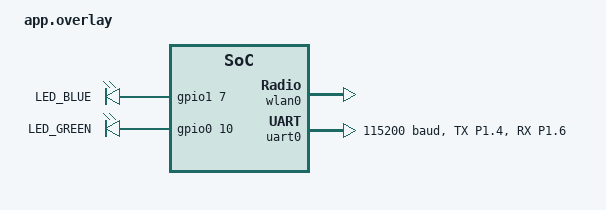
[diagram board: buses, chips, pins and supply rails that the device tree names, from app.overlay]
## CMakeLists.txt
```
#
# Copyright (c) 2022 Nordic Semiconductor ASA
#
# SPDX-License-Identifier: LicenseRef-Nordic-5-Clause
#

cmake_minimum_required(VERSION 3.20.0)

find_package(Zephyr REQUIRED HINTS $ENV{ZEPHYR_BASE})
project(nrf_wifi_sta)

target_include_directories(app PUBLIC
	${CMAKE_CURRENT_SOURCE_DIR}/src
	${ZEPHYR_BASE}/subsys/net/ip
)

target_sources(app PRIVATE
	src/main.c
	src/wt_app.c
	src/wt_ble.c
	src/wt_common.c
	src/wt_leds.c
	src/wt_radio.c
	src/wt_shell.c
	src/wt_stream.c
	src/wt_wifi.c
)
```

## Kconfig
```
#
# Copyright (c) 2022 Nordic Semiconductor
#
# SPDX-License-Identifier: LicenseRef-Nordic-5-Clause
#

source "Kconfig.zephyr"

menu "Nordic Sta sample"

config CONNECTION_IDLE_TIMEOUT
	int "Time to be waited for a station to connect"
	default 30

config NRF70_QSPI_ENCRYPTION_KEY
	string "16 bytes QSPI encryption key, only for testing purposes"
	depends on BOARD_NRF7002DK_NRF5340_CPUAPP
	help
	  Specify the QSPI encryption key

config STA_CONN_TIMEOUT_SEC
	int "Overall Connection timeout i.e., time to be waited for a station to connect and get an IP address"
	# Zephyr DHCP retry is 1 minute, so set the default to 70 seconds
	default 70
	# 512 has no special meaning, just a reasonable upper limit
	range 0 512
	help
	  Specify the connection timeout, in seconds. This is the overall timeout i.e., time to be waited for
	  a station to connect and get an IP address. DHCP retries should be taken into account when setting
	  this value. If the timeout is set to 0, the connection will not timeout.

choice WT02E40E_DEFAULT_RADIO_MODE
	prompt "Default WT02E40E radio mode"
	default WT02E40E_DEFAULT_BLE
	help
	  Select which radio path starts automatically at boot. Wi-Fi can be
	  left disabled while the external antenna is missing, then started
	  from the UART/RTT shell later.

config WT02E40E_DEFAULT_IDLE
	bool "Idle, commands only"

config WT02E40E_DEFAULT_BLE
	bool "BLE advertising"

config WT02E40E_DEFAULT_WIFI
	bool "Wi-Fi station"

config WT02E40E_DEFAULT_BOTH
	bool "BLE advertising and Wi-Fi station"

endchoice

config STA_SAMPLE_START_WIFI_THREAD_STACK_SIZE
	int "Stack size for Wi-Fi start thread"
	default 4096
	help
	  Set the stack size for the Wi-Fi start thread.

endmenu
```

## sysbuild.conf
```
# Build nRF7002 Wi-Fi support and the nRF5340 network-core BLE controller image.
SB_CONFIG_WIFI_NRF70=y
SB_CONFIG_NETCORE_HCI_IPC=y
```

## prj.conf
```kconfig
# WT02E40E nRF5340 + nRF7002 Wi-Fi/BLE command bring-up.

# Default boot behavior while the Wi-Fi antenna is missing.
CONFIG_WT02E40E_DEFAULT_BLE=y

# Wi-Fi
CONFIG_WIFI=y
CONFIG_WIFI_NRF70=y
CONFIG_WIFI_NM_WPA_SUPPLICANT=y
CONFIG_WIFI_READY_LIB=y

# Wi-Fi credentials. Static credentials are the compiled fallback, and the UART/RTT
# shell can store a runtime override in the Zephyr credentials backend.
CONFIG_WIFI_CREDENTIALS=y
CONFIG_WIFI_CREDENTIALS_MAX_ENTRIES=4
CONFIG_WIFI_CREDENTIALS_BACKEND_SETTINGS=y
CONFIG_SETTINGS=y
CONFIG_SETTINGS_NVS=y
CONFIG_NVS=y
CONFIG_FLASH=y
CONFIG_FLASH_PAGE_LAYOUT=y
CONFIG_FLASH_MAP=y
CONFIG_WIFI_CREDENTIALS_STATIC=y
CONFIG_WIFI_CREDENTIALS_STATIC_SSID="Myssid"
CONFIG_WIFI_CREDENTIALS_STATIC_PASSWORD="Mypassword"

# BLE peripheral advertising.
CONFIG_BT=y
CONFIG_BT_PERIPHERAL=y
CONFIG_BT_DEVICE_NAME="WT02E40E-CMD"
CONFIG_BT_DEVICE_NAME_DYNAMIC=y
CONFIG_BT_DEVICE_NAME_MAX=32
CONFIG_BT_MAX_CONN=1
CONFIG_BT_BUF_ACL_TX_COUNT=3
CONFIG_BT_BUF_EVT_RX_COUNT=10
CONFIG_BT_RX_STACK_SIZE=2048

# BLE ATT MTU / L2CAP buffers.
# App-level command/status payloads are capped at 255 bytes, but notifications use
# the negotiated ATT MTU dynamically. With MTU 256, usable ATT payload is 253 bytes.
CONFIG_BT_L2CAP_TX_MTU=256
CONFIG_BT_BUF_ACL_RX_SIZE=260
CONFIG_BT_BUF_ACL_TX_SIZE=260

# UART/RTT command shell.
CONFIG_SERIAL=y
CONFIG_CONSOLE=y
CONFIG_UART_CONSOLE=y
CONFIG_UART_INTERRUPT_DRIVEN=y
CONFIG_SHELL=y
CONFIG_SHELL_BACKEND_SERIAL=y
CONFIG_SHELL_BACKEND_RTT=y
CONFIG_SHELL_STACK_SIZE=4096
CONFIG_SHELL_CMDS_RESIZE=n
CONFIG_USE_SEGGER_RTT=y

# Networking
CONFIG_NETWORKING=y
CONFIG_NET_SOCKETS=y
CONFIG_NET_LOG=y
CONFIG_NET_IPV4=y
CONFIG_NET_UDP=y
CONFIG_NET_TCP=y
CONFIG_NET_DHCPV4=y

CONFIG_NET_PKT_RX_COUNT=16
CONFIG_NET_PKT_TX_COUNT=16
CONFIG_NRF70_RX_NUM_BUFS=16

# Wi-Fi memory tuning from Nordic STA sample.
CONFIG_NET_BUF_RX_COUNT=16
CONFIG_NET_BUF_TX_COUNT=32
CONFIG_HEAP_MEM_POOL_SIZE=37000
CONFIG_HEAP_MEM_POOL_IGNORE_MIN=y
CONFIG_NRF_WIFI_CTRL_HEAP_SIZE=20000
CONFIG_NRF_WIFI_DATA_HEAP_SIZE=40000
CONFIG_NET_TC_TX_COUNT=1

CONFIG_NET_IF_UNICAST_IPV4_ADDR_COUNT=1
CONFIG_NET_MAX_CONTEXTS=5
CONFIG_NET_CONTEXT_SYNC_RECV=y

CONFIG_NET_L2_ETHERNET=y
CONFIG_NET_L2_ETHERNET_MGMT=y

CONFIG_NET_CONFIG_SETTINGS=y
CONFIG_NET_CONFIG_INIT_TIMEOUT=0
CONFIG_NET_CONFIG_MY_IPV4_ADDR="192.168.1.99"
CONFIG_NET_CONFIG_MY_IPV4_NETMASK="255.255.255.0"
CONFIG_NET_CONFIG_MY_IPV4_GW="192.168.1.1"

CONFIG_ZVFS_POLL_MAX=10

# Memory
CONFIG_MAIN_STACK_SIZE=5200
CONFIG_NET_TX_STACK_SIZE=4096
CONFIG_NET_RX_STACK_SIZE=4096
CONFIG_STA_SAMPLE_START_WIFI_THREAD_STACK_SIZE=6144
CONFIG_SYSTEM_WORKQUEUE_STACK_SIZE=4096

# Kernel
CONFIG_GPIO=y
CONFIG_ENTROPY_GENERATOR=y
CONFIG_INIT_STACKS=y

# Logging / debug
CONFIG_LOG=y
CONFIG_LOG_DEFAULT_LEVEL=3
CONFIG_LOG_BUFFER_SIZE=4096
CONFIG_LOG_BACKEND_RTT=n
CONFIG_LOG_BACKEND_UART=n
CONFIG_SHELL_LOG_BACKEND=y
CONFIG_POSIX_TIMERS=y
CONFIG_STACK_SENTINEL=y
CONFIG_DEBUG_COREDUMP=y
CONFIG_DEBUG_COREDUMP_BACKEND_LOGGING=y
CONFIG_DEBUG_COREDUMP_MEMORY_DUMP_MIN=y

# Printing scan/status results can put pressure on queues in crowded environments.
CONFIG_NET_MGMT_EVENT_QUEUE_TIMEOUT=5000

# Reboot command support
CONFIG_REBOOT=y
```

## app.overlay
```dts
#include <zephyr/dt-bindings/pinctrl/nrf-pinctrl.h>

/*
 * WT02E40E local MAC address for the nRF7002 Wi-Fi interface when OTP
 * is not programmed. This is locally administered, not a public OUI.
 */
&wlan0 {
	local-mac-address = [f6 ce 36 00 00 01];
};

/*
 * WT02E40E carrier schematic:
 *   Blue LED:  P1.07 -> LED/resistor -> GND
 *   Green LED: P0.10 -> LED/resistor -> GND
 */
&led0 {
	gpios = <&gpio1 7 GPIO_ACTIVE_HIGH>;
	label = "LED_BLUE";
};

&led1 {
	gpios = <&gpio0 10 GPIO_ACTIVE_HIGH>;
	label = "LED_GREEN";
};

/*
 * UART command shell on the carrier nets:
 *   nRF P1.04 UART_TX -> PA23/RX1 net
 *   nRF P1.06 UART_RX -> PA22/TX1 net
 */
&pinctrl {
	uart0_wt02e40e_default: uart0_wt02e40e_default {
		group1 {
			psels = <NRF_PSEL(UART_TX, 1, 4)>,
				<NRF_PSEL(UART_RX, 1, 6)>;
		};
	};

	uart0_wt02e40e_sleep: uart0_wt02e40e_sleep {
		group1 {
			psels = <NRF_PSEL(UART_TX, 1, 4)>,
				<NRF_PSEL(UART_RX, 1, 6)>;
			low-power-enable;
		};
	};
};

&uart0 {
	status = "okay";
	current-speed = <115200>;
	pinctrl-0 = <&uart0_wt02e40e_default>;
	pinctrl-1 = <&uart0_wt02e40e_sleep>;
	pinctrl-names = "default", "sleep";
};
```

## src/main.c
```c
/*
 * Copyright (c) 2022 Nordic Semiconductor ASA
 *
 * SPDX-License-Identifier: LicenseRef-Nordic-5-Clause
 */

/** @file
 * @brief WT02E40E Wi-Fi/BLE command bridge entry point.
 */

#include <errno.h>

#include <zephyr/kernel.h>
#include <zephyr/logging/log.h>
#include <zephyr/sys/util.h>

#include "wt_app.h"
#include "wt_ble.h"
#include "wt_leds.h"
#include "wt_radio.h"
#include "wt_wifi.h"

LOG_MODULE_REGISTER(wt_main, CONFIG_LOG_DEFAULT_LEVEL);

int main(void)
{
	int ret;

	LOG_INF("Starting %s with CPU frequency: %d MHz", CONFIG_BOARD, SystemCoreClock / MHZ(1));

	wt_leds_start();
	wt_ble_init();

	ret = wt_wifi_init();
	if (ret) {
		return ret;
	}

#ifdef CONFIG_WIFI_READY_LIB
	ret = wt_wifi_register_ready_callback();
	if (ret) {
		return ret;
	}
	wt_wifi_start_worker();
#else
	LOG_ERR("CONFIG_WIFI_READY_LIB is required for this command sample");
	return -ENOTSUP;
#endif

	ret = wt_app_settings_init();
	if (ret) {
		LOG_WRN("App settings load skipped/failed: %d", ret);
	}

	k_sleep(K_SECONDS(1));
	wt_radio_apply_default_mode();

	while (1) {
		k_sleep(K_FOREVER);
	}

	return 0;
}
```

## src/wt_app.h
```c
#ifndef WT_APP_H
#define WT_APP_H

#include <stdbool.h>
#include <stddef.h>
#include <stdint.h>

#define WT_APP_FW_VERSION "0.3.9-wifi-led-idle"

int wt_app_settings_init(void);
int wt_app_config_save(void);
int wt_app_config_reset(void);

const char *wt_app_boot_mode_get(void);
int wt_app_boot_mode_set(const char *mode);

int wt_app_version_format(char *buf, size_t size);
int wt_app_id_format(char *buf, size_t size);
int wt_app_config_format(char *buf, size_t size, bool json);
int wt_app_ble_status_format(char *buf, size_t size, bool json);
int wt_app_wifi_status_format(char *buf, size_t size, bool json);
int wt_app_fw_status_format(char *buf, size_t size);

int wt_app_parse_delay_ms(const char *text, uint32_t *delay_ms);
int wt_app_delayed_radio_apply(const char *mode_or_action, uint32_t delay_ms);
int wt_app_reboot_schedule(bool bootloader, uint32_t delay_ms);

bool wt_app_bridge_ble_enabled(void);
bool wt_app_bridge_uart_enabled(void);
bool wt_app_bridge_wifi_enabled(void);
const char *wt_app_bridge_target_ip_get(void);
uint16_t wt_app_bridge_target_port_get(void);
int wt_app_bridge_set(const char *path, bool enable);
int wt_app_bridge_target_set(const char *ip, const char *port_text);
int wt_app_bridge_status_format(char *buf, size_t size, bool json);
int wt_app_bridge_send(const uint8_t *data, size_t len, char *rsp, size_t rsp_len);

int wt_app_ping_execute(char **argv, size_t argc, char *rsp, size_t rsp_len);
int wt_app_boot_command(char **argv, size_t argc, char *rsp, size_t rsp_len);
int wt_app_bridge_command(char **argv, size_t argc, char *rsp, size_t rsp_len);
int wt_app_fw_command(char **argv, size_t argc, char *rsp, size_t rsp_len);
int wt_app_led_command(char **argv, size_t argc, char *rsp, size_t rsp_len);

#endif /* WT_APP_H */
```

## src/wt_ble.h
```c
#ifndef WT_BLE_H
#define WT_BLE_H

#include <stdbool.h>
#include <stddef.h>
#include <stdint.h>

bool wt_ble_is_requested(void);
bool wt_ble_is_ready(void);
bool wt_ble_is_advertising(void);
bool wt_ble_is_connected(void);
bool wt_ble_tx_notify_is_enabled(void);
bool wt_ble_status_notify_is_enabled(void);
bool wt_ble_cmd_response_notify_is_enabled(void);
const char *wt_ble_name_get(void);
int wt_ble_name_set(const char *name);

void wt_ble_init(void);
int wt_ble_service_start(void);
int wt_ble_service_stop(void);
int wt_ble_transmit_payload(const uint8_t *data, size_t len);
int wt_ble_status_format(char *buf, size_t size);

#endif /* WT_BLE_H */
```

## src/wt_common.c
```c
#include <errno.h>
#include <stdint.h>
#include <stdlib.h>
#include <string.h>

#include <zephyr/sys/util.h>

#include "wt_common.h"

const char *wt_onoff_txt(bool state)
{
	return state ? "on" : "off";
}

int wt_build_payload_from_argv(size_t start_arg, size_t argc, char **argv,
				       char *buf, size_t buf_len)
{
	size_t offset = 0;

	if (start_arg >= argc) {
		return -EINVAL;
	}

	for (size_t i = start_arg; i < argc; i++) {
		const char *arg = argv[i];
		size_t arg_len = strlen(arg);

		if (i > start_arg) {
			if (offset + 1 >= buf_len) {
				return -EMSGSIZE;
			}
			buf[offset++] = ' ';
		}

		if (offset + arg_len >= buf_len) {
			return -EMSGSIZE;
		}

		memcpy(&buf[offset], arg, arg_len);
		offset += arg_len;
	}

	buf[offset] = '\0';
	return (int)offset;
}

static bool wt_is_cmd_space(char c)
{
	return c == ' ' || c == '\t' || c == '\r' || c == '\n';
}

static char wt_unescape_char(char c)
{
	switch (c) {
	case 'n':
		return '\n';
	case 'r':
		return '\r';
	case 't':
		return '\t';
	default:
		return c;
	}
}

int wt_split_args_quoted(char *line, char **argv, size_t argv_max)
{
	char *read = line;
	size_t argc = 0;

	if (!line || !argv || argv_max == 0) {
		return -EINVAL;
	}

	while (*read) {
		char *write;
		char quote = '\0';

		while (*read && wt_is_cmd_space(*read)) {
			*read++ = '\0';
		}

		if (!*read) {
			break;
		}

		if (argc >= argv_max) {
			return -E2BIG;
		}

		argv[argc++] = read;
		write = read;

		while (*read) {
			char c = *read++;

			if (quote) {
				if (c == '\\' && *read) {
					*write++ = wt_unescape_char(*read++);
					continue;
				}
				if (c == quote) {
					quote = '\0';
					continue;
				}
				*write++ = c;
				continue;
			}

			if (c == '\'' || c == '"') {
				quote = c;
				continue;
			}

			if (wt_is_cmd_space(c)) {
				break;
			}

			if (c == '\\' && *read) {
				*write++ = wt_unescape_char(*read++);
				continue;
			}

			*write++ = c;
		}

		if (quote) {
			return -EINVAL;
		}

		*write = '\0';
	}

	return (int)argc;
}

int wt_parse_udp_port(const char *port_text, uint16_t *port)
{
	char *end = NULL;
	long parsed = strtol(port_text, &end, 10);

	if (!end || *end != '\0' || parsed <= 0 || parsed > UINT16_MAX) {
		return -EINVAL;
	}

	*port = (uint16_t)parsed;
	return 0;
}
```

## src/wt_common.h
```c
#ifndef WT_COMMON_H
#define WT_COMMON_H

#include <stddef.h>
#include <stdint.h>
#include <stdbool.h>

const char *wt_onoff_txt(bool state);
int wt_build_payload_from_argv(size_t start_arg, size_t argc, char **argv,
				       char *buf, size_t buf_len);
int wt_parse_udp_port(const char *port_text, uint16_t *port);
int wt_split_args_quoted(char *line, char **argv, size_t argv_max);

#endif /* WT_COMMON_H */
```

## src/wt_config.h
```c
#ifndef WT_CONFIG_H
#define WT_CONFIG_H

#define STATUS_POLLING_MS 300
#define LED_SLEEP_TIME_MS 250
#define WT_BLE_NOTIFY_RETRY_COUNT 8
#define WT_BLE_NOTIFY_RETRY_DELAY_MS 20
#define WT_BLE_NOTIFY_INTER_CHUNK_DELAY_MS 12
#define WT_TX_PAYLOAD_MAX 244
#define WT_BLE_NOTIFY_APP_PAYLOAD_MAX 244
#define WT_BLE_STREAM_CHUNK_OVERHEAD 8
#define WT_BLE_STATUS_TEXT_MAX 250
#define WT_BLE_CMD_TEXT_MAX 255
#define WT_BLE_CMD_RSP_TEXT_MAX 250
#define WT_BLE_STATUS_PING_MS 5000
#define WT_BLE_ADV_RESTART_DELAY_MS 250
#define WT_BLE_SELF_STOP_DELAY_MS 500
#define WT_WIFI_CRED_TIMEOUT_SEC CONFIG_STA_CONN_TIMEOUT_SEC

#define WT_WIFI_CMD_UDP_PORT 5001
#define WT_WIFI_CMD_RX_TEXT_MAX 255
#define WT_WIFI_CMD_RSP_TEXT_MAX 250
#define WT_WIFI_CMD_THREAD_STACK_SIZE 4096
#define WT_WIFI_CMD_THREAD_PRIORITY 7
#define WT_WIFI_DISCOVERY_UDP_PORT 5000
#define WT_WIFI_DISCOVERY_INTERVAL_MS 5000
#define WT_WIFI_DISCOVERY_PAYLOAD_MAX 250
#define WT_WIFI_SCAN_MAX_RESULTS 10
#define WT_WIFI_SCAN_TIMEOUT_MS 12000
#define WT_BLE_NAME_MAX 31

#define WT_APP_BOOT_MODE_MAX 8
#define WT_APP_DELAYED_ACTION_MAX 16
#define WT_APP_REBOOT_DELAY_MS 500
#define WT_APP_BRIDGE_TARGET_MAX 47

#endif /* WT_CONFIG_H */
```

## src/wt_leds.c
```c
#include <errno.h>
#include <stdbool.h>
#include <stddef.h>
#include <stdint.h>
#include <string.h>

#include <zephyr/drivers/gpio.h>
#include <zephyr/kernel.h>
#include <zephyr/logging/log.h>
#include <zephyr/sys/atomic.h>
#include <zephyr/sys/printk.h>
#include <zephyr/sys/util.h>

#include "wt_ble.h"
#include "wt_config.h"
#include "wt_leds.h"
#include "wt_wifi.h"

LOG_MODULE_REGISTER(wt_leds, CONFIG_LOG_DEFAULT_LEVEL);

#define WT_LED_MASK_BLE BIT(0)
#define WT_LED_MASK_WIFI BIT(1)
#define WT_LED_MASK_ACTIVITY BIT(2)
#define WT_LED_MASK_ALERT BIT(3)
#define WT_LED_ACTIVITY_TICKS 4
#define WT_LED_BLE_REPORT_TICKS 2
#define WT_LED_ALERT_TICKS 12
#define WT_LED_TEST_TICKS 24

#if DT_NODE_HAS_STATUS(DT_ALIAS(led0), okay)
static const struct gpio_dt_spec led_ble = GPIO_DT_SPEC_GET(DT_ALIAS(led0), gpios);
#define WT_HAS_LED_BLE 1
#else
#define WT_HAS_LED_BLE 0
#endif

#if DT_NODE_HAS_STATUS(DT_ALIAS(led1), okay)
static const struct gpio_dt_spec led_wifi = GPIO_DT_SPEC_GET(DT_ALIAS(led1), gpios);
#define WT_HAS_LED_WIFI 1
#else
#define WT_HAS_LED_WIFI 0
#endif

#if DT_NODE_HAS_STATUS(DT_ALIAS(led2), okay)
static const struct gpio_dt_spec led_activity = GPIO_DT_SPEC_GET(DT_ALIAS(led2), gpios);
#define WT_HAS_LED_ACTIVITY 1
#else
#define WT_HAS_LED_ACTIVITY 0
#endif

#if DT_NODE_HAS_STATUS(DT_ALIAS(led3), okay)
static const struct gpio_dt_spec led_alert = GPIO_DT_SPEC_GET(DT_ALIAS(led3), gpios);
#define WT_HAS_LED_ALERT 1
#else
#define WT_HAS_LED_ALERT 0
#endif

static atomic_t ble_activity_ticks;
static atomic_t ble_report_ticks;
static atomic_t wifi_activity_ticks;
static atomic_t bridge_activity_ticks;
static atomic_t alert_activity_ticks;
static atomic_t test_ticks;
static atomic_t test_mask;

static int configure_indicator_led(const struct gpio_dt_spec *led, const char *name)
{
	int ret;

	if (!led) {
		return -ENODEV;
	}

	if (!gpio_is_ready_dt(led)) {
		LOG_ERR("%s GPIO device is not ready", name);
		return -ENODEV;
	}

	ret = gpio_pin_configure_dt(led, GPIO_OUTPUT_INACTIVE);
	if (ret < 0) {
		LOG_ERR("Failed to configure %s LED: %d", name, ret);
		return ret;
	}

	return 0;
}

static void set_indicator_led(const struct gpio_dt_spec *led, int on)
{
	if (led && gpio_is_ready_dt(led)) {
		gpio_pin_set_dt(led, on);
	}
}

static bool consume_pulse(atomic_t *ticks)
{
	atomic_val_t value = atomic_get(ticks);

	if (value <= 0) {
		return false;
	}

	atomic_dec(ticks);
	return true;
}

static bool led_test_applies(uint32_t mask, uint32_t bit)
{
	return (mask & bit) != 0U;
}

static bool led_target_mask(const char *target, uint32_t *mask)
{
	if (!target || !mask) {
		return false;
	}

	if (!strcmp(target, "all") || !strcmp(target, "test")) {
		*mask = WT_LED_MASK_BLE | WT_LED_MASK_WIFI | WT_LED_MASK_ACTIVITY | WT_LED_MASK_ALERT;
		return true;
	}
	if (!strcmp(target, "ble") || !strcmp(target, "bt")) {
		*mask = WT_LED_MASK_BLE;
		return true;
	}
	if (!strcmp(target, "wifi") || !strcmp(target, "wi-fi")) {
		*mask = WT_LED_MASK_WIFI;
		return true;
	}
	if (!strcmp(target, "bridge") || !strcmp(target, "activity") || !strcmp(target, "tx")) {
		*mask = WT_LED_MASK_ACTIVITY;
		return true;
	}
	if (!strcmp(target, "alert") || !strcmp(target, "error") || !strcmp(target, "err")) {
		*mask = WT_LED_MASK_ALERT;
		return true;
	}

	return false;
}

static void indicator_leds_thread(void *p1, void *p2, void *p3)
{
	ARG_UNUSED(p1);
	ARG_UNUSED(p2);
	ARG_UNUSED(p3);

	uint32_t tick = 0;

#if WT_HAS_LED_BLE
	(void)configure_indicator_led(&led_ble, "ble/status");
#endif
#if WT_HAS_LED_WIFI
	(void)configure_indicator_led(&led_wifi, "wifi/status");
#endif
#if WT_HAS_LED_ACTIVITY
	(void)configure_indicator_led(&led_activity, "bridge/activity");
#endif
#if WT_HAS_LED_ALERT
	(void)configure_indicator_led(&led_alert, "alert/error");
#endif

	while (1) {
		const bool fast = (tick & 1U) != 0U;
		const bool medium = ((tick / 2U) & 1U) != 0U;
		const bool slow = ((tick / 4U) & 1U) != 0U;
		const bool heartbeat = (tick % 8U) == 0U;
		const bool double_pulse = (tick % 12U) == 0U || (tick % 12U) == 2U;
		bool ble_led_on = false;
		bool wifi_led_on = false;
		bool activity_led_on = false;
		bool alert_led_on = false;
		atomic_val_t active_test_ticks = atomic_get(&test_ticks);
		uint32_t active_test_mask = (uint32_t)atomic_get(&test_mask);

		if (wt_ble_is_connected()) {
			ble_led_on = true;
		} else if (wt_ble_is_advertising()) {
			ble_led_on = medium;
		} else if (wt_ble_is_requested() && wt_ble_is_ready()) {
			ble_led_on = heartbeat;
		} else if (wt_ble_is_requested()) {
			ble_led_on = slow;
		}

		if (wt_wifi_scan_is_running()) {
			wifi_led_on = fast;
		} else if (wt_wifi_has_ipv4()) {
			wifi_led_on = true;
		} else if (wt_wifi_is_associated()) {
			wifi_led_on = double_pulse;
		} else if (wt_wifi_is_requested()) {
			wifi_led_on = slow;
		}

		if (consume_pulse(&ble_activity_ticks)) {
			ble_led_on = true;
			activity_led_on = true;
		}
		if (consume_pulse(&ble_report_ticks)) {
			ble_led_on = wt_ble_is_connected() ? false : true;
			activity_led_on = true;
		}
		if (consume_pulse(&wifi_activity_ticks)) {
			wifi_led_on = true;
			activity_led_on = true;
		}
		if (consume_pulse(&bridge_activity_ticks)) {
			activity_led_on = true;
		}
		if (consume_pulse(&alert_activity_ticks)) {
			alert_led_on = fast;
		}

		if (active_test_ticks > 0) {
			atomic_dec(&test_ticks);
			if (led_test_applies(active_test_mask, WT_LED_MASK_BLE)) {
				ble_led_on = fast;
			}
			if (led_test_applies(active_test_mask, WT_LED_MASK_WIFI)) {
				wifi_led_on = fast;
			}
			if (led_test_applies(active_test_mask, WT_LED_MASK_ACTIVITY)) {
				activity_led_on = fast;
			}
			if (led_test_applies(active_test_mask, WT_LED_MASK_ALERT)) {
				alert_led_on = fast;
			}
		}

#if WT_HAS_LED_BLE
		set_indicator_led(&led_ble, ble_led_on ? 1 : 0);
#endif
#if WT_HAS_LED_WIFI
		set_indicator_led(&led_wifi, wifi_led_on ? 1 : 0);
#endif
#if WT_HAS_LED_ACTIVITY
		set_indicator_led(&led_activity, activity_led_on ? 1 : 0);
#endif
#if WT_HAS_LED_ALERT
		set_indicator_led(&led_alert, alert_led_on ? 1 : 0);
#endif

		tick++;
		k_msleep(LED_SLEEP_TIME_MS);
	}
}

K_THREAD_DEFINE(led_thread_id, 1024, indicator_leds_thread, NULL, NULL, NULL, 7, 0, 0);

void wt_leds_start(void)
{
	/* LED thread starts automatically through K_THREAD_DEFINE. */
}

void wt_leds_ble_activity(void)
{
	atomic_set(&ble_activity_ticks, WT_LED_ACTIVITY_TICKS);
}

void wt_leds_ble_report_activity(void)
{
	atomic_set(&ble_report_ticks, WT_LED_BLE_REPORT_TICKS);
}

void wt_leds_wifi_activity(void)
{
	atomic_set(&wifi_activity_ticks, WT_LED_ACTIVITY_TICKS);
}

void wt_leds_bridge_activity(void)
{
	atomic_set(&bridge_activity_ticks, WT_LED_ACTIVITY_TICKS);
}

void wt_leds_error_activity(void)
{
	atomic_set(&alert_activity_ticks, WT_LED_ALERT_TICKS);
}

int wt_leds_test(const char *target)
{
	uint32_t mask;

	if (!target || target[0] == '\0') {
		target = "all";
	}

	if (!led_target_mask(target, &mask)) {
		return -EINVAL;
	}

	atomic_set(&test_mask, (atomic_val_t)mask);
	atomic_set(&test_ticks, WT_LED_TEST_TICKS);
	return 0;
}

int wt_leds_status_format(char *buf, size_t size)
{
	if (!buf || size == 0) {
		return -EINVAL;
	}

	return snprintk(buf, size,
		"led status ble=conn solid/cmd-rsp+tx dip/adv blink/ready pulse wifi=ip solid/scan fast/assoc double/req slow activity=tx pulse alert=error pulse leds=%d%d%d%d",
		WT_HAS_LED_BLE, WT_HAS_LED_WIFI, WT_HAS_LED_ACTIVITY, WT_HAS_LED_ALERT);
}
```

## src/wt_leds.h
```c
#ifndef WT_LEDS_H
#define WT_LEDS_H

#include <stddef.h>

void wt_leds_start(void);
void wt_leds_ble_activity(void);
void wt_leds_ble_report_activity(void);
void wt_leds_wifi_activity(void);
void wt_leds_bridge_activity(void);
void wt_leds_error_activity(void);
int wt_leds_test(const char *target);
int wt_leds_status_format(char *buf, size_t size);

#endif /* WT_LEDS_H */
```

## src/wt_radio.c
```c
#include <errno.h>
#include <string.h>

#include <zephyr/logging/log.h>

#include "wt_app.h"
#include "wt_ble.h"
#include "wt_radio.h"
#include "wt_wifi.h"

LOG_MODULE_REGISTER(wt_radio, CONFIG_LOG_DEFAULT_LEVEL);

int wt_radio_mode_apply(const char *mode)
{
	if (!strcmp(mode, "idle") || !strcmp(mode, "off")) {
		(void)wt_wifi_service_set(false);
		(void)wt_ble_service_stop();
		LOG_INF("Radio mode: idle");
		return 0;
	}

	if (!strcmp(mode, "ble") || !strcmp(mode, "bt")) {
		(void)wt_wifi_service_set(false);
		return wt_ble_service_start();
	}

	if (!strcmp(mode, "wifi") || !strcmp(mode, "wi-fi")) {
		(void)wt_ble_service_stop();
		return wt_wifi_service_set(true);
	}

	if (!strcmp(mode, "both")) {
		int ret_ble = wt_ble_service_start();
		int ret_wifi = wt_wifi_service_set(true);

		return ret_ble ? ret_ble : ret_wifi;
	}

	LOG_ERR("Unknown mode: %s", mode);
	return -EINVAL;
}

void wt_radio_apply_default_mode(void)
{
	const char *mode = wt_app_boot_mode_get();

	LOG_INF("Applying boot radio mode: %s", mode);
	(void)wt_radio_mode_apply(mode);
}
```

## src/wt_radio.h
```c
#ifndef WT_RADIO_H
#define WT_RADIO_H

int wt_radio_mode_apply(const char *mode);
void wt_radio_apply_default_mode(void);

#endif /* WT_RADIO_H */
```

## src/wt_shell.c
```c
#include <errno.h>
#include <stdint.h>
#include <string.h>

#include <zephyr/shell/shell.h>
#include <zephyr/sys/printk.h>
#include <zephyr/sys/util.h>

#include "wt_app.h"
#include "wt_ble.h"
#include "wt_common.h"
#include "wt_config.h"
#include "wt_radio.h"
#include "wt_wifi.h"

static char tx_payload_buf[WT_TX_PAYLOAD_MAX];
static char shell_rsp_buf[WT_BLE_CMD_RSP_TEXT_MAX];

static int shell_cmd_wt_status(const struct shell *sh, size_t argc, char **argv)
{
	bool json = argc >= 2 && !strcmp(argv[1], "json");

	if (json) {
		(void)wt_app_config_format(shell_rsp_buf, sizeof(shell_rsp_buf), true);
		shell_print(sh, "%s", shell_rsp_buf);
		return 0;
	}

	shell_print(sh, "WT02E40E radio state");
	shell_print(sh, "  Name: %s", wt_ble_name_get());
	shell_print(sh, "  Wi-Fi requested: %s", wt_onoff_txt(wt_wifi_is_requested()));
	shell_print(sh, "  Wi-Fi associated: %s", wt_onoff_txt(wt_wifi_is_associated()));
	shell_print(sh, "  Wi-Fi IPv4 bound: %s", wt_onoff_txt(wt_wifi_has_ipv4()));
	shell_print(sh, "  Wi-Fi UDP command server: %s on port %u",
		    wt_onoff_txt(wt_wifi_cmd_is_enabled()), wt_wifi_cmd_port());
	shell_print(sh, "  Wi-Fi discovery beacon: %s on port %u",
		    wt_onoff_txt(wt_wifi_discovery_is_enabled()), WT_WIFI_DISCOVERY_UDP_PORT);
	shell_print(sh, "  Stored Wi-Fi credentials:");
	(void)wt_wifi_credentials_print_list(sh);
	shell_print(sh, "  BLE requested: %s", wt_onoff_txt(wt_ble_is_requested()));
	shell_print(sh, "  BLE initialized: %s", wt_onoff_txt(wt_ble_is_ready()));
	shell_print(sh, "  BLE advertising: %s", wt_onoff_txt(wt_ble_is_advertising()));
	shell_print(sh, "  BLE connected: %s", wt_onoff_txt(wt_ble_is_connected()));
	shell_print(sh, "  BLE TX notify: %s", wt_onoff_txt(wt_ble_tx_notify_is_enabled()));
	shell_print(sh, "  BLE status notify: %s", wt_onoff_txt(wt_ble_status_notify_is_enabled()));
	shell_print(sh, "  BLE command response notify: %s", wt_onoff_txt(wt_ble_cmd_response_notify_is_enabled()));

	return 0;
}

static int shell_cmd_wt_id(const struct shell *sh, size_t argc, char **argv)
{
	ARG_UNUSED(argc);
	ARG_UNUSED(argv);

	(void)wt_app_id_format(shell_rsp_buf, sizeof(shell_rsp_buf));
	shell_print(sh, "%s", shell_rsp_buf);
	return 0;
}

static int shell_cmd_wt_version(const struct shell *sh, size_t argc, char **argv)
{
	ARG_UNUSED(argc);
	ARG_UNUSED(argv);

	(void)wt_app_version_format(shell_rsp_buf, sizeof(shell_rsp_buf));
	shell_print(sh, "%s", shell_rsp_buf);
	return 0;
}

static int shell_cmd_wt_config(const struct shell *sh, size_t argc, char **argv)
{
	bool json = argc >= 2 && !strcmp(argv[1], "json");

	if (argc >= 2 && !strcmp(argv[1], "save")) {
		int ret = wt_app_config_save();
		if (ret) {
			shell_error(sh, "config save failed: %d", ret);
			return ret;
		}
		shell_print(sh, "config saved");
		return 0;
	}

	if (argc >= 2 && !strcmp(argv[1], "reset")) {
		int ret = wt_app_config_reset();
		if (ret) {
			shell_error(sh, "config reset failed: %d", ret);
			return ret;
		}
		shell_print(sh, "config reset");
		return 0;
	}

	(void)wt_app_config_format(shell_rsp_buf, sizeof(shell_rsp_buf), json);
	shell_print(sh, "%s", shell_rsp_buf);
	return 0;
}

static int shell_cmd_wt_name(const struct shell *sh, size_t argc, char **argv)
{
	int ret;

	if (argc < 2 || !strcmp(argv[1], "get")) {
		shell_print(sh, "BLE name: %s", wt_ble_name_get());
		return 0;
	}

	if (!strcmp(argv[1], "set")) {
		if (argc < 3) {
			shell_print(sh, "usage: wt name set <ble-name>");
			return -EINVAL;
		}
		ret = wt_ble_name_set(argv[2]);
	} else {
		ret = wt_ble_name_set(argv[1]);
	}

	if (ret) {
		shell_error(sh, "BLE name set failed: %d", ret);
		return ret;
	}

	shell_print(sh, "BLE name: %s", wt_ble_name_get());
	return 0;
}


static int shell_cmd_wt_boot(const struct shell *sh, size_t argc, char **argv)
{
	int ret = wt_app_boot_command(argv, argc, shell_rsp_buf, sizeof(shell_rsp_buf));

	if (ret < 0) {
		shell_error(sh, "%s", shell_rsp_buf);
		return ret;
	}

	shell_print(sh, "%s", shell_rsp_buf);
	return 0;
}

static int shell_cmd_wt_fw(const struct shell *sh, size_t argc, char **argv)
{
	int ret = wt_app_fw_command(argv, argc, shell_rsp_buf, sizeof(shell_rsp_buf));

	if (ret < 0) {
		shell_error(sh, "%s", shell_rsp_buf);
		return ret;
	}

	shell_print(sh, "%s", shell_rsp_buf);
	return 0;
}

static int shell_cmd_wt_reboot(const struct shell *sh, size_t argc, char **argv)
{
	char *fw_argv[4];
	size_t fw_argc = 2;
	int ret;

	fw_argv[0] = "fw";
	fw_argv[1] = "reboot";
	if (argc >= 2) {
		fw_argv[2] = argv[1];
		fw_argc = 3;
	}
	if (argc >= 3) {
		fw_argv[3] = argv[2];
		fw_argc = 4;
	}

	ret = wt_app_fw_command(fw_argv, fw_argc, shell_rsp_buf, sizeof(shell_rsp_buf));
	if (ret < 0) {
		shell_error(sh, "%s", shell_rsp_buf);
		return ret;
	}
	shell_print(sh, "%s", shell_rsp_buf);
	return 0;
}

static int shell_cmd_wt_bridge(const struct shell *sh, size_t argc, char **argv)
{
	int ret = wt_app_bridge_command(argv, argc, shell_rsp_buf, sizeof(shell_rsp_buf));

	if (ret < 0) {
		shell_error(sh, "%s", shell_rsp_buf);
		return ret;
	}

	shell_print(sh, "%s", shell_rsp_buf);
	return 0;
}

static int shell_cmd_wt_led(const struct shell *sh, size_t argc, char **argv)
{
	int ret = wt_app_led_command(argv, argc, shell_rsp_buf, sizeof(shell_rsp_buf));

	if (ret < 0) {
		shell_error(sh, "%s", shell_rsp_buf);
		return ret;
	}

	shell_print(sh, "%s", shell_rsp_buf);
	return 0;
}

static int shell_cmd_wt_ping(const struct shell *sh, size_t argc, char **argv)
{
	int ret = wt_app_ping_execute(argv, argc, shell_rsp_buf, sizeof(shell_rsp_buf));

	if (ret < 0) {
		shell_error(sh, "%s", shell_rsp_buf);
		return ret;
	}

	shell_print(sh, "%s", shell_rsp_buf);
	return 0;
}

static int shell_cmd_wt_mode(const struct shell *sh, size_t argc, char **argv)
{
	uint32_t delay_ms = 0;
	int ret;

	if (argc < 2) {
		shell_print(sh, "usage: wt mode idle|ble|wifi|both [delay]");
		return -EINVAL;
	}

	if (argc >= 3) {
		ret = wt_app_parse_delay_ms(argv[2], &delay_ms);
		if (ret) {
			shell_error(sh, "bad delay: %s", argv[2]);
			return ret;
		}
	}

	ret = wt_app_delayed_radio_apply(argv[1], delay_ms);
	if (ret) {
		shell_error(sh, "mode command failed: %d", ret);
		return ret;
	}

	if (delay_ms) {
		shell_print(sh, "mode %s scheduled in %u ms", argv[1], delay_ms);
	} else {
		shell_print(sh, "mode set to %s", argv[1]);
	}
	return 0;
}

static int shell_cmd_wt_discovery(const struct shell *sh, size_t argc, char **argv)
{
	int ret;

	if (argc < 2 || !strcmp(argv[1], "status")) {
		shell_print(sh, "Wi-Fi discovery beacon: %s on port %u interval %ums",
			    wt_onoff_txt(wt_wifi_discovery_is_enabled()),
			    WT_WIFI_DISCOVERY_UDP_PORT, WT_WIFI_DISCOVERY_INTERVAL_MS);
		return 0;
	}

	if (!strcmp(argv[1], "on") || !strcmp(argv[1], "start")) {
		ret = wt_wifi_discovery_service_set(true);
	} else if (!strcmp(argv[1], "off") || !strcmp(argv[1], "stop")) {
		ret = wt_wifi_discovery_service_set(false);
	} else {
		shell_print(sh, "usage: wt discovery on|off|status");
		return -EINVAL;
	}

	if (ret) {
		shell_error(sh, "discovery command failed: %d", ret);
		return ret;
	}

	shell_print(sh, "discovery %s", argv[1]);
	return 0;
}

static int shell_cmd_wt_wifi(const struct shell *sh, size_t argc, char **argv)
{
	int ret = 0;

	if (argc < 2) {
		shell_print(sh, "usage: wt wifi on|off|status|reconnect|scan|cmd|discovery|cred");
		return -EINVAL;
	}

	if (!strcmp(argv[1], "on") || !strcmp(argv[1], "start")) {
		ret = wt_wifi_service_set(true);
	} else if (!strcmp(argv[1], "off") || !strcmp(argv[1], "stop")) {
		uint32_t delay_ms = 0;
		if (argc >= 3) {
			ret = wt_app_parse_delay_ms(argv[2], &delay_ms);
			if (ret) {
				shell_error(sh, "bad delay: %s", argv[2]);
				return ret;
			}
		}
		ret = wt_app_delayed_radio_apply("wifi_off", delay_ms);
		if (!ret && delay_ms) {
			shell_print(sh, "wifi off scheduled in %u ms", delay_ms);
			return 0;
		}
	} else if (!strcmp(argv[1], "status")) {
		if (argc >= 3 && !strcmp(argv[2], "json")) {
			(void)wt_app_wifi_status_format(shell_rsp_buf, sizeof(shell_rsp_buf), true);
			shell_print(sh, "%s", shell_rsp_buf);
			return 0;
		}
		(void)wt_app_wifi_status_format(shell_rsp_buf, sizeof(shell_rsp_buf), false);
		shell_print(sh, "%s", shell_rsp_buf);
		ret = wt_wifi_status_log();
	} else if (!strcmp(argv[1], "reconnect")) {
		ret = wt_wifi_reconnect_if_requested();
		if (!wt_wifi_is_requested()) {
			ret = wt_wifi_service_set(true);
		}
	} else if (!strcmp(argv[1], "scan") || !strcmp(argv[1], "apscan") || !strcmp(argv[1], "networks")) {
		ret = wt_wifi_scan_command((char **)argv, argc, shell_rsp_buf, sizeof(shell_rsp_buf));
		if (ret < 0) {
			shell_error(sh, "%s", shell_rsp_buf);
			return ret;
		}
		shell_print(sh, "%s", shell_rsp_buf);
		return 0;
	} else if (!strcmp(argv[1], "cmd") || !strcmp(argv[1], "command") || !strcmp(argv[1], "commands")) {
		if (argc < 3 || !strcmp(argv[2], "status")) {
			shell_print(sh, "Wi-Fi UDP command server: %s on port %u",
				    wt_onoff_txt(wt_wifi_cmd_is_enabled()), wt_wifi_cmd_port());
			return 0;
		}
		if (!strcmp(argv[2], "on") || !strcmp(argv[2], "start")) {
			ret = wt_wifi_cmd_service_set(true);
		} else if (!strcmp(argv[2], "off") || !strcmp(argv[2], "stop")) {
			ret = wt_wifi_cmd_service_set(false);
		} else if (!strcmp(argv[2], "port")) {
			uint16_t port;
			if (argc < 4) {
				shell_print(sh, "Wi-Fi UDP command port: %u", wt_wifi_cmd_port());
				return 0;
			}
			ret = wt_parse_udp_port(argv[3], &port);
			if (ret) {
				shell_error(sh, "invalid Wi-Fi command port: %s", argv[3]);
				return ret;
			}
			ret = wt_wifi_cmd_port_set(port);
			if (!ret) {
				shell_print(sh, "Wi-Fi UDP command port: %u", wt_wifi_cmd_port());
			}
		} else {
			shell_print(sh, "usage: wt wifi cmd on|off|status|port [port]");
			return -EINVAL;
		}
	} else if (!strcmp(argv[1], "discovery") || !strcmp(argv[1], "discover")) {
		if (argc < 3 || !strcmp(argv[2], "status")) {
			return shell_cmd_wt_discovery(sh, 1, argv);
		}
		char *disc_argv[] = { "discovery", argv[2] };
		return shell_cmd_wt_discovery(sh, 2, disc_argv);
	} else if (!strcmp(argv[1], "cred") || !strcmp(argv[1], "creds")) {
		return wt_wifi_credentials_shell(sh, argc, argv);
	} else {
		shell_print(sh, "usage: wt wifi on|off|status|reconnect|scan|cmd|discovery|cred");
		return -EINVAL;
	}

	if (ret) {
		shell_error(sh, "wifi command failed: %d", ret);
		return ret;
	}

	return 0;
}

static int shell_cmd_wt_ble(const struct shell *sh, size_t argc, char **argv)
{
	int ret;

	if (argc < 2) {
		shell_print(sh, "usage: wt ble on|off|status|name [get|set <name>]");
		return -EINVAL;
	}

	if (!strcmp(argv[1], "name")) {
		if (argc < 3 || !strcmp(argv[2], "get")) {
			shell_print(sh, "BLE name: %s", wt_ble_name_get());
			return 0;
		}
		if (!strcmp(argv[2], "set")) {
			if (argc < 4) {
				shell_print(sh, "usage: wt ble name set <name>");
				return -EINVAL;
			}
			ret = wt_ble_name_set(argv[3]);
		} else {
			ret = wt_ble_name_set(argv[2]);
		}
		if (ret) {
			shell_error(sh, "BLE name set failed: %d", ret);
			return ret;
		}
		return 0;
	}

	if (!strcmp(argv[1], "on") || !strcmp(argv[1], "start")) {
		ret = wt_ble_service_start();
	} else if (!strcmp(argv[1], "off") || !strcmp(argv[1], "stop")) {
		uint32_t delay_ms = 0;
		if (argc >= 3) {
			ret = wt_app_parse_delay_ms(argv[2], &delay_ms);
			if (ret) {
				shell_error(sh, "bad delay: %s", argv[2]);
				return ret;
			}
		}
		ret = wt_app_delayed_radio_apply("ble_off", delay_ms);
		if (!ret && delay_ms) {
			shell_print(sh, "ble off scheduled in %u ms", delay_ms);
			return 0;
		}
	} else if (!strcmp(argv[1], "status")) {
		(void)wt_app_ble_status_format(shell_rsp_buf, sizeof(shell_rsp_buf), argc >= 3 && !strcmp(argv[2], "json"));
		shell_print(sh, "%s", shell_rsp_buf);
		return 0;
	} else {
		shell_print(sh, "usage: wt ble on|off|status|name [get|set <name>]");
		return -EINVAL;
	}

	if (ret) {
		shell_error(sh, "ble command failed: %d", ret);
		return ret;
	}

	return 0;
}

static int shell_tx_uart_payload(size_t argc, char **argv, size_t payload_arg)
{
	int payload_len;

	payload_len = wt_build_payload_from_argv(payload_arg, argc, argv,
				tx_payload_buf, sizeof(tx_payload_buf));
	if (payload_len < 0) {
		return payload_len;
	}

	printk("UART TX: ");
	for (int i = 0; i < payload_len; i++) {
		printk("%c", tx_payload_buf[i]);
	}
	printk("\r\n");

	return payload_len;
}

static int shell_cmd_wt_tx(const struct shell *sh, size_t argc, char **argv)
{
	int payload_len;
	int ret;

	if (argc < 3) {
		shell_print(sh, "usage: wt tx ble <message>");
		shell_print(sh, "       wt tx uart <message>");
		shell_print(sh, "       wt tx wifi <ipv4> <port> <message>");
		shell_print(sh, "       wt tx both <ipv4> <port> <message>");
		return -EINVAL;
	}

	if (!strcmp(argv[1], "ble") || !strcmp(argv[1], "bt")) {
		payload_len = wt_build_payload_from_argv(2, argc, argv,
					tx_payload_buf, sizeof(tx_payload_buf));
		if (payload_len < 0) {
			shell_error(sh, "payload build failed: %d", payload_len);
			return payload_len;
		}

		ret = wt_ble_transmit_payload((const uint8_t *)tx_payload_buf, payload_len);
		if (ret) {
			shell_error(sh, "BLE transmit failed: %d", ret);
			if (ret == -EACCES) {
				shell_print(sh, "enable notifications on the WT TX characteristic first");
			}
			return ret;
		}

		shell_print(sh, "BLE TX: %d bytes", payload_len);
		return 0;
	}

	if (!strcmp(argv[1], "uart") || !strcmp(argv[1], "serial")) {
		payload_len = shell_tx_uart_payload(argc, argv, 2);
		if (payload_len < 0) {
			shell_error(sh, "UART payload build failed: %d", payload_len);
			return payload_len;
		}
		shell_print(sh, "UART TX: %d bytes", payload_len);
		return 0;
	}

	if (!strcmp(argv[1], "wifi") || !strcmp(argv[1], "udp")) {
		if (argc < 5) {
			shell_print(sh, "usage: wt tx wifi <ipv4> <port> <message>");
			return -EINVAL;
		}

		payload_len = wt_build_payload_from_argv(4, argc, argv,
					tx_payload_buf, sizeof(tx_payload_buf));
		if (payload_len < 0) {
			shell_error(sh, "payload build failed: %d", payload_len);
			return payload_len;
		}

		ret = wt_wifi_udp_transmit_payload(argv[2], argv[3],
						(const uint8_t *)tx_payload_buf, payload_len);
		if (ret) {
			shell_error(sh, "Wi-Fi UDP transmit failed: %d", ret);
			return ret;
		}

		shell_print(sh, "Wi-Fi UDP TX: %d bytes to %s:%s",
			    payload_len, argv[2], argv[3]);
		return 0;
	}

	if (!strcmp(argv[1], "both") || !strcmp(argv[1], "all")) {
		if (argc < 5) {
			shell_print(sh, "usage: wt tx both <ipv4> <port> <message>");
			return -EINVAL;
		}

		payload_len = wt_build_payload_from_argv(4, argc, argv,
					tx_payload_buf, sizeof(tx_payload_buf));
		if (payload_len < 0) {
			shell_error(sh, "payload build failed: %d", payload_len);
			return payload_len;
		}

		ret = wt_wifi_udp_transmit_payload(argv[2], argv[3],
						(const uint8_t *)tx_payload_buf, payload_len);
		if (ret) {
			shell_error(sh, "Wi-Fi UDP transmit failed: %d", ret);
			return ret;
		}

		(void)shell_tx_uart_payload(argc, argv, 4);
		ret = wt_ble_transmit_payload((const uint8_t *)tx_payload_buf, payload_len);
		if (ret && ret != -EACCES) {
			shell_error(sh, "BLE transmit failed after Wi-Fi/UART TX: %d", ret);
			return ret;
		}

		shell_print(sh, "both TX: %d bytes%s", payload_len,
			    ret == -EACCES ? " (BLE notify off)" : "");
		return 0;
	}

	shell_print(sh, "usage: wt tx ble|uart|wifi|both ...");
	return -EINVAL;
}

SHELL_STATIC_SUBCMD_SET_CREATE(wt_subcmds,
	SHELL_CMD_ARG(status, NULL, "Show WT02E40E radio state, optionally: json", shell_cmd_wt_status, 1, 1),
	SHELL_CMD_ARG(id, NULL, "Show compact device identity", shell_cmd_wt_id, 1, 0),
	SHELL_CMD_ARG(version, NULL, "Show firmware/build version", shell_cmd_wt_version, 1, 0),
	SHELL_CMD_ARG(fw, NULL, "Firmware: status, reboot [delay], reboot bootloader [delay]", shell_cmd_wt_fw, 1, 3),
	SHELL_CMD_ARG(reboot, NULL, "Reboot, optionally: bootloader [delay]", shell_cmd_wt_reboot, 1, 2),
	SHELL_CMD_ARG(config, NULL, "Show config, config json, config save, config reset", shell_cmd_wt_config, 1, 1),
	SHELL_CMD_ARG(boot, NULL, "Boot config: status, mode <idle|ble|wifi|both>", shell_cmd_wt_boot, 1, 2),
	SHELL_CMD_ARG(bridge, NULL, "Bridge rules and send", shell_cmd_wt_bridge, 1, WT_TX_PAYLOAD_MAX),
	SHELL_CMD_ARG(led, NULL, "LED indicators: status, test, pulse", shell_cmd_wt_led, 1, 2),
	SHELL_CMD_ARG(indicator, NULL, "LED indicators: status, test, pulse", shell_cmd_wt_led, 1, 2),
	SHELL_CMD_ARG(ping, NULL, "Ping local|uart|ble|wifi <ip> <port>", shell_cmd_wt_ping, 1, 3),
	SHELL_CMD_ARG(name, NULL, "Get/set BLE advertised name", shell_cmd_wt_name, 1, WT_BLE_NAME_MAX),
	SHELL_CMD_ARG(mode, NULL, "Set radio mode: idle, ble, wifi, both [delay]", shell_cmd_wt_mode, 2, 1),
	SHELL_CMD_ARG(discovery, NULL, "Control UDP discovery: on, off, status", shell_cmd_wt_discovery, 1, 1),
	SHELL_CMD_ARG(wifi, NULL, "Control Wi-Fi: on, off, status, reconnect, scan, cmd, discovery, cred", shell_cmd_wt_wifi, 2, WT_TX_PAYLOAD_MAX),
	SHELL_CMD_ARG(ble, NULL, "Control BLE: on, off, status, name", shell_cmd_wt_ble, 2, WT_BLE_NAME_MAX),
	SHELL_CMD_ARG(tx, NULL, "Transmit: ble <msg>, uart <msg>, wifi <ip> <port> <msg>, both <ip> <port> <msg>", shell_cmd_wt_tx, 3, WT_TX_PAYLOAD_MAX),
	SHELL_SUBCMD_SET_END);

SHELL_CMD_REGISTER(wt, &wt_subcmds, "WT02E40E radio commands", NULL);
```
